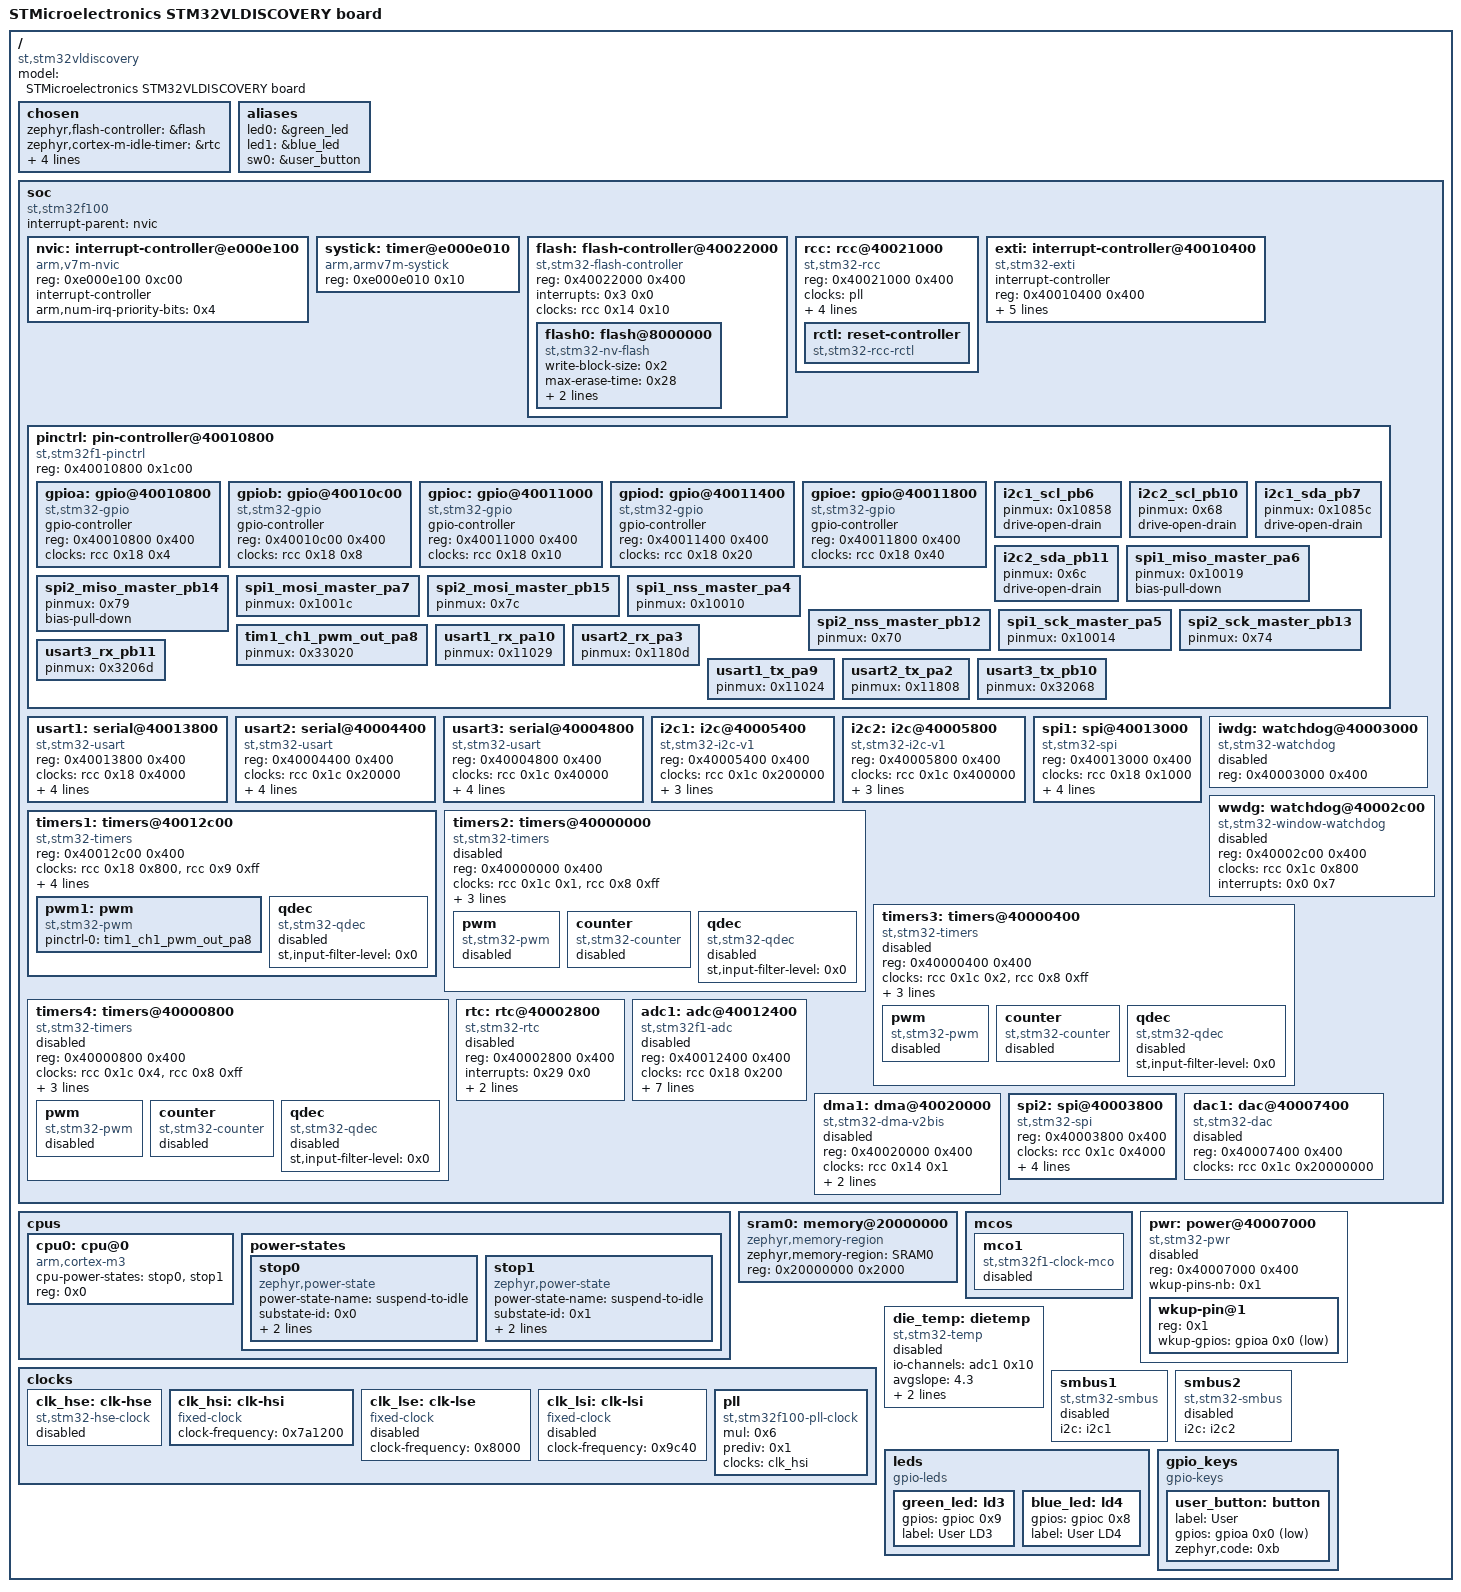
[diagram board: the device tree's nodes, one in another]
/dts-v1/;

/* node '/' defined in zephyr/dts/common/skeleton.dtsi:9 */
/ {
	#address-cells = < 0x1 >;                            /* in zephyr/dts/common/skeleton.dtsi:10 */
	#size-cells = < 0x1 >;                               /* in zephyr/dts/common/skeleton.dtsi:11 */
	model = "STMicroelectronics STM32VLDISCOVERY board"; /* in zephyr/boards/st/stm32vl_disco/stm32vl_disco.dts:13 */
	compatible = "st,stm32vldiscovery";                  /* in zephyr/boards/st/stm32vl_disco/stm32vl_disco.dts:14 */

	/* node '/chosen' defined in zephyr/dts/common/skeleton.dtsi:13 */
	chosen {
		zephyr,flash-controller = &flash;  /* in zephyr/dts/arm/st/f1/stm32f1.dtsi:25 */
		zephyr,cortex-m-idle-timer = &rtc; /* in zephyr/dts/arm/st/f1/stm32f1.dtsi:26 */
		zephyr,console = &usart1;          /* in zephyr/boards/st/stm32vl_disco/stm32vl_disco.dts:17 */
		zephyr,shell-uart = &usart1;       /* in zephyr/boards/st/stm32vl_disco/stm32vl_disco.dts:18 */
		zephyr,sram = &sram0;              /* in zephyr/boards/st/stm32vl_disco/stm32vl_disco.dts:19 */
		zephyr,flash = &flash0;            /* in zephyr/boards/st/stm32vl_disco/stm32vl_disco.dts:20 */
	};

	/* node '/aliases' defined in zephyr/dts/common/skeleton.dtsi:15 */
	aliases {
		led0 = &green_led;  /* in zephyr/boards/st/stm32vl_disco/stm32vl_disco.dts:48 */
		led1 = &blue_led;   /* in zephyr/boards/st/stm32vl_disco/stm32vl_disco.dts:49 */
		sw0 = &user_button; /* in zephyr/boards/st/stm32vl_disco/stm32vl_disco.dts:50 */
	};

	/* node '/soc' defined in zephyr/dts/arm/armv7-m.dtsi:6 */
	soc {
		#address-cells = < 0x1 >;     /* in zephyr/dts/arm/armv7-m.dtsi:7 */
		#size-cells = < 0x1 >;        /* in zephyr/dts/arm/armv7-m.dtsi:8 */
		interrupt-parent = < &nvic >; /* in zephyr/dts/arm/armv7-m.dtsi:10 */
		ranges;                       /* in zephyr/dts/arm/armv7-m.dtsi:11 */
		compatible = "st,stm32f100",
		             "st,stm32f1",
		             "simple-bus";    /* in zephyr/dts/arm/st/f1/stm32f100Xb.dtsi:27 */

		/* node '/soc/interrupt-controller@e000e100' defined in zephyr/dts/arm/armv7-m.dtsi:13 */
		nvic: interrupt-controller@e000e100 {
			#address-cells = < 0x1 >;            /* in zephyr/dts/arm/armv7-m.dtsi:14 */
			compatible = "arm,v7m-nvic";         /* in zephyr/dts/arm/armv7-m.dtsi:15 */
			reg = < 0xe000e100 0xc00 >;          /* in zephyr/dts/arm/armv7-m.dtsi:16 */
			interrupt-controller;                /* in zephyr/dts/arm/armv7-m.dtsi:17 */
			#interrupt-cells = < 0x2 >;          /* in zephyr/dts/arm/armv7-m.dtsi:18 */
			arm,num-irq-priority-bits = < 0x4 >; /* in zephyr/dts/arm/st/f1/stm32f1.dtsi:461 */
			phandle = < 0x1 >;                   /* in zephyr/dts/arm/armv7-m.dtsi:10 */
		};

		/* node '/soc/timer@e000e010' defined in zephyr/dts/arm/armv7-m.dtsi:21 */
		systick: timer@e000e010 {
			compatible = "arm,armv7m-systick"; /* in zephyr/dts/arm/armv7-m.dtsi:22 */
			reg = < 0xe000e010 0x10 >;         /* in zephyr/dts/arm/armv7-m.dtsi:23 */
		};

		/* node '/soc/flash-controller@40022000' defined in zephyr/dts/arm/st/f1/stm32f1.dtsi:107 */
		flash: flash-controller@40022000 {
			compatible = "st,stm32-flash-controller",
			             "st,stm32f1-flash-controller"; /* in zephyr/dts/arm/st/f1/stm32f1.dtsi:108 */
			reg = < 0x40022000 0x400 >;                 /* in zephyr/dts/arm/st/f1/stm32f1.dtsi:109 */
			interrupts = < 0x3 0x0 >;                   /* in zephyr/dts/arm/st/f1/stm32f1.dtsi:110 */
			clocks = < &rcc 0x14 0x10 >;                /* in zephyr/dts/arm/st/f1/stm32f1.dtsi:111 */
			#address-cells = < 0x1 >;                   /* in zephyr/dts/arm/st/f1/stm32f1.dtsi:113 */
			#size-cells = < 0x1 >;                      /* in zephyr/dts/arm/st/f1/stm32f1.dtsi:114 */

			/* node '/soc/flash-controller@40022000/flash@8000000' defined in zephyr/dts/arm/st/f1/stm32f1.dtsi:116 */
			flash0: flash@8000000 {
				compatible = "st,stm32-nv-flash",
				             "soc-nv-flash";      /* in zephyr/dts/arm/st/f1/stm32f1.dtsi:117 */
				write-block-size = < 0x2 >;       /* in zephyr/dts/arm/st/f1/stm32f1.dtsi:119 */
				max-erase-time = < 0x28 >;        /* in zephyr/dts/arm/st/f1/stm32f1.dtsi:121 */
				reg = < 0x8000000 0x20000 >;      /* in zephyr/dts/arm/st/f1/stm32f100Xb.dtsi:31 */
				erase-block-size = < 0x400 >;     /* in zephyr/dts/arm/st/f1/stm32f100Xb.dtsi:32 */
			};
		};

		/* node '/soc/rcc@40021000' defined in zephyr/dts/arm/st/f1/stm32f1.dtsi:125 */
		rcc: rcc@40021000 {
			compatible = "st,stm32-rcc";     /* in zephyr/dts/arm/st/f1/stm32f1.dtsi:126 */
			#clock-cells = < 0x2 >;          /* in zephyr/dts/arm/st/f1/stm32f1.dtsi:127 */
			reg = < 0x40021000 0x400 >;      /* in zephyr/dts/arm/st/f1/stm32f1.dtsi:128 */
			clocks = < &pll >;               /* in zephyr/boards/st/stm32vl_disco/stm32vl_disco.dts:66 */
			clock-frequency = < 0x16e3600 >; /* in zephyr/boards/st/stm32vl_disco/stm32vl_disco.dts:67 */
			ahb-prescaler = < 0x1 >;         /* in zephyr/boards/st/stm32vl_disco/stm32vl_disco.dts:68 */
			apb1-prescaler = < 0x2 >;        /* in zephyr/boards/st/stm32vl_disco/stm32vl_disco.dts:69 */
			apb2-prescaler = < 0x1 >;        /* in zephyr/boards/st/stm32vl_disco/stm32vl_disco.dts:70 */
			phandle = < 0x2 >;               /* in zephyr/dts/arm/st/f1/stm32f1.dtsi:111 */

			/* node '/soc/rcc@40021000/reset-controller' defined in zephyr/dts/arm/st/f1/stm32f1.dtsi:130 */
			rctl: reset-controller {
				compatible = "st,stm32-rcc-rctl"; /* in zephyr/dts/arm/st/f1/stm32f1.dtsi:131 */
				#reset-cells = < 0x1 >;           /* in zephyr/dts/arm/st/f1/stm32f1.dtsi:132 */
				phandle = < 0x4 >;                /* in zephyr/dts/arm/st/f1/stm32f1.dtsi:202 */
			};
		};

		/* node '/soc/interrupt-controller@40010400' defined in zephyr/dts/arm/st/f1/stm32f1.dtsi:136 */
		exti: interrupt-controller@40010400 {
			compatible = "st,stm32-exti";  /* in zephyr/dts/arm/st/f1/stm32f1.dtsi:137 */
			interrupt-controller;          /* in zephyr/dts/arm/st/f1/stm32f1.dtsi:138 */
			#interrupt-cells = < 0x1 >;    /* in zephyr/dts/arm/st/f1/stm32f1.dtsi:139 */
			#address-cells = < 0x0 >;      /* in zephyr/dts/arm/st/f1/stm32f1.dtsi:140 */
			reg = < 0x40010400 0x400 >;    /* in zephyr/dts/arm/st/f1/stm32f1.dtsi:141 */
			num-lines = < 0x20 >;          /* in zephyr/dts/arm/st/f1/stm32f1.dtsi:142 */
			interrupts = < 0x6 0x0 >,
			             < 0x7 0x0 >,
			             < 0x8 0x0 >,
			             < 0x9 0x0 >,
			             < 0xa 0x0 >,
			             < 0x17 0x0 >,
			             < 0x28 0x0 >;     /* in zephyr/dts/arm/st/f1/stm32f1.dtsi:143 */
			interrupt-names = "line0",
			                  "line1",
			                  "line2",
			                  "line3",
			                  "line4",
			                  "line5-9",
			                  "line10-15"; /* in zephyr/dts/arm/st/f1/stm32f1.dtsi:145 */
			line-ranges = < 0x0 0x1 >,
			              < 0x1 0x1 >,
			              < 0x2 0x1 >,
			              < 0x3 0x1 >,
			              < 0x4 0x1 >,
			              < 0x5 0x5 >,
			              < 0xa 0x6 >;     /* in zephyr/dts/arm/st/f1/stm32f1.dtsi:147 */
		};

		/* node '/soc/pin-controller@40010800' defined in zephyr/dts/arm/st/f1/stm32f1.dtsi:151 */
		pinctrl: pin-controller@40010800 {
			compatible = "st,stm32f1-pinctrl"; /* in zephyr/dts/arm/st/f1/stm32f1.dtsi:152 */
			#address-cells = < 0x1 >;          /* in zephyr/dts/arm/st/f1/stm32f1.dtsi:153 */
			#size-cells = < 0x1 >;             /* in zephyr/dts/arm/st/f1/stm32f1.dtsi:154 */
			reg = < 0x40010800 0x1c00 >;       /* in zephyr/dts/arm/st/f1/stm32f1.dtsi:155 */

			/* node '/soc/pin-controller@40010800/gpio@40010800' defined in zephyr/dts/arm/st/f1/stm32f1.dtsi:157 */
			gpioa: gpio@40010800 {
				compatible = "st,stm32-gpio"; /* in zephyr/dts/arm/st/f1/stm32f1.dtsi:158 */
				gpio-controller;              /* in zephyr/dts/arm/st/f1/stm32f1.dtsi:159 */
				#gpio-cells = < 0x2 >;        /* in zephyr/dts/arm/st/f1/stm32f1.dtsi:160 */
				reg = < 0x40010800 0x400 >;   /* in zephyr/dts/arm/st/f1/stm32f1.dtsi:161 */
				clocks = < &rcc 0x18 0x4 >;   /* in zephyr/dts/arm/st/f1/stm32f1.dtsi:162 */
				phandle = < 0x1b >;           /* in zephyr/dts/arm/st/f1/stm32f1.dtsi:430 */
			};

			/* node '/soc/pin-controller@40010800/gpio@40010c00' defined in zephyr/dts/arm/st/f1/stm32f1.dtsi:165 */
			gpiob: gpio@40010c00 {
				compatible = "st,stm32-gpio"; /* in zephyr/dts/arm/st/f1/stm32f1.dtsi:166 */
				gpio-controller;              /* in zephyr/dts/arm/st/f1/stm32f1.dtsi:167 */
				#gpio-cells = < 0x2 >;        /* in zephyr/dts/arm/st/f1/stm32f1.dtsi:168 */
				reg = < 0x40010c00 0x400 >;   /* in zephyr/dts/arm/st/f1/stm32f1.dtsi:169 */
				clocks = < &rcc 0x18 0x8 >;   /* in zephyr/dts/arm/st/f1/stm32f1.dtsi:170 */
			};

			/* node '/soc/pin-controller@40010800/gpio@40011000' defined in zephyr/dts/arm/st/f1/stm32f1.dtsi:173 */
			gpioc: gpio@40011000 {
				compatible = "st,stm32-gpio"; /* in zephyr/dts/arm/st/f1/stm32f1.dtsi:174 */
				gpio-controller;              /* in zephyr/dts/arm/st/f1/stm32f1.dtsi:175 */
				#gpio-cells = < 0x2 >;        /* in zephyr/dts/arm/st/f1/stm32f1.dtsi:176 */
				reg = < 0x40011000 0x400 >;   /* in zephyr/dts/arm/st/f1/stm32f1.dtsi:177 */
				clocks = < &rcc 0x18 0x10 >;  /* in zephyr/dts/arm/st/f1/stm32f1.dtsi:178 */
				phandle = < 0x1f >;           /* in zephyr/boards/st/stm32vl_disco/stm32vl_disco.dts:27 */
			};

			/* node '/soc/pin-controller@40010800/gpio@40011400' defined in zephyr/dts/arm/st/f1/stm32f1.dtsi:181 */
			gpiod: gpio@40011400 {
				compatible = "st,stm32-gpio"; /* in zephyr/dts/arm/st/f1/stm32f1.dtsi:182 */
				gpio-controller;              /* in zephyr/dts/arm/st/f1/stm32f1.dtsi:183 */
				#gpio-cells = < 0x2 >;        /* in zephyr/dts/arm/st/f1/stm32f1.dtsi:184 */
				reg = < 0x40011400 0x400 >;   /* in zephyr/dts/arm/st/f1/stm32f1.dtsi:185 */
				clocks = < &rcc 0x18 0x20 >;  /* in zephyr/dts/arm/st/f1/stm32f1.dtsi:186 */
			};

			/* node '/soc/pin-controller@40010800/gpio@40011800' defined in zephyr/dts/arm/st/f1/stm32f1.dtsi:189 */
			gpioe: gpio@40011800 {
				compatible = "st,stm32-gpio"; /* in zephyr/dts/arm/st/f1/stm32f1.dtsi:190 */
				gpio-controller;              /* in zephyr/dts/arm/st/f1/stm32f1.dtsi:191 */
				#gpio-cells = < 0x2 >;        /* in zephyr/dts/arm/st/f1/stm32f1.dtsi:192 */
				reg = < 0x40011800 0x400 >;   /* in zephyr/dts/arm/st/f1/stm32f1.dtsi:193 */
				clocks = < &rcc 0x18 0x40 >;  /* in zephyr/dts/arm/st/f1/stm32f1.dtsi:194 */
			};

			/* node '/soc/pin-controller@40010800/i2c1_scl_pb6' defined in modules/hal/stm32/dts/st/f1/stm32f100r(8-b)tx-pinctrl.dtsi:297 */
			i2c1_scl_pb6: i2c1_scl_pb6 {
				pinmux = < 0x10858 >; /* in modules/hal/stm32/dts/st/f1/stm32f100r(8-b)tx-pinctrl.dtsi:298 */
				drive-open-drain;     /* in modules/hal/stm32/dts/st/f1/stm32f100r(8-b)tx-pinctrl.dtsi:299 */
				phandle = < 0xb >;    /* in zephyr/boards/st/stm32vl_disco/stm32vl_disco.dts:95 */
			};

			/* node '/soc/pin-controller@40010800/i2c2_scl_pb10' defined in modules/hal/stm32/dts/st/f1/stm32f100r(8-b)tx-pinctrl.dtsi:307 */
			i2c2_scl_pb10: i2c2_scl_pb10 {
				pinmux = < 0x68 >; /* in modules/hal/stm32/dts/st/f1/stm32f100r(8-b)tx-pinctrl.dtsi:308 */
				drive-open-drain;  /* in modules/hal/stm32/dts/st/f1/stm32f100r(8-b)tx-pinctrl.dtsi:309 */
				phandle = < 0xd >; /* in zephyr/boards/st/stm32vl_disco/stm32vl_disco.dts:102 */
			};

			/* node '/soc/pin-controller@40010800/i2c1_sda_pb7' defined in modules/hal/stm32/dts/st/f1/stm32f100r(8-b)tx-pinctrl.dtsi:314 */
			i2c1_sda_pb7: i2c1_sda_pb7 {
				pinmux = < 0x1085c >; /* in modules/hal/stm32/dts/st/f1/stm32f100r(8-b)tx-pinctrl.dtsi:315 */
				drive-open-drain;     /* in modules/hal/stm32/dts/st/f1/stm32f100r(8-b)tx-pinctrl.dtsi:316 */
				phandle = < 0xc >;    /* in zephyr/boards/st/stm32vl_disco/stm32vl_disco.dts:95 */
			};

			/* node '/soc/pin-controller@40010800/i2c2_sda_pb11' defined in modules/hal/stm32/dts/st/f1/stm32f100r(8-b)tx-pinctrl.dtsi:324 */
			i2c2_sda_pb11: i2c2_sda_pb11 {
				pinmux = < 0x6c >; /* in modules/hal/stm32/dts/st/f1/stm32f100r(8-b)tx-pinctrl.dtsi:325 */
				drive-open-drain;  /* in modules/hal/stm32/dts/st/f1/stm32f100r(8-b)tx-pinctrl.dtsi:326 */
				phandle = < 0xe >; /* in zephyr/boards/st/stm32vl_disco/stm32vl_disco.dts:102 */
			};

			/* node '/soc/pin-controller@40010800/spi1_miso_master_pa6' defined in modules/hal/stm32/dts/st/f1/stm32f100r(8-b)tx-pinctrl.dtsi:365 */
			spi1_miso_master_pa6: spi1_miso_master_pa6 {
				pinmux = < 0x10019 >; /* in modules/hal/stm32/dts/st/f1/stm32f100r(8-b)tx-pinctrl.dtsi:366 */
				bias-pull-down;       /* in modules/hal/stm32/dts/st/f1/stm32f100r(8-b)tx-pinctrl.dtsi:367 */
				phandle = < 0x11 >;   /* in zephyr/boards/st/stm32vl_disco/stm32vl_disco.dts:109 */
			};

			/* node '/soc/pin-controller@40010800/spi2_miso_master_pb14' defined in modules/hal/stm32/dts/st/f1/stm32f100r(8-b)tx-pinctrl.dtsi:375 */
			spi2_miso_master_pb14: spi2_miso_master_pb14 {
				pinmux = < 0x79 >;  /* in modules/hal/stm32/dts/st/f1/stm32f100r(8-b)tx-pinctrl.dtsi:376 */
				bias-pull-down;     /* in modules/hal/stm32/dts/st/f1/stm32f100r(8-b)tx-pinctrl.dtsi:377 */
				phandle = < 0x16 >; /* in zephyr/boards/st/stm32vl_disco/stm32vl_disco.dts:116 */
			};

			/* node '/soc/pin-controller@40010800/spi1_mosi_master_pa7' defined in modules/hal/stm32/dts/st/f1/stm32f100r(8-b)tx-pinctrl.dtsi:382 */
			spi1_mosi_master_pa7: spi1_mosi_master_pa7 {
				pinmux = < 0x1001c >; /* in modules/hal/stm32/dts/st/f1/stm32f100r(8-b)tx-pinctrl.dtsi:383 */
				phandle = < 0x12 >;   /* in zephyr/boards/st/stm32vl_disco/stm32vl_disco.dts:109 */
			};

			/* node '/soc/pin-controller@40010800/spi2_mosi_master_pb15' defined in modules/hal/stm32/dts/st/f1/stm32f100r(8-b)tx-pinctrl.dtsi:390 */
			spi2_mosi_master_pb15: spi2_mosi_master_pb15 {
				pinmux = < 0x7c >;  /* in modules/hal/stm32/dts/st/f1/stm32f100r(8-b)tx-pinctrl.dtsi:391 */
				phandle = < 0x17 >; /* in zephyr/boards/st/stm32vl_disco/stm32vl_disco.dts:116 */
			};

			/* node '/soc/pin-controller@40010800/spi1_nss_master_pa4' defined in modules/hal/stm32/dts/st/f1/stm32f100r(8-b)tx-pinctrl.dtsi:396 */
			spi1_nss_master_pa4: spi1_nss_master_pa4 {
				pinmux = < 0x10010 >; /* in modules/hal/stm32/dts/st/f1/stm32f100r(8-b)tx-pinctrl.dtsi:397 */
				phandle = < 0xf >;    /* in zephyr/boards/st/stm32vl_disco/stm32vl_disco.dts:109 */
			};

			/* node '/soc/pin-controller@40010800/spi2_nss_master_pb12' defined in modules/hal/stm32/dts/st/f1/stm32f100r(8-b)tx-pinctrl.dtsi:404 */
			spi2_nss_master_pb12: spi2_nss_master_pb12 {
				pinmux = < 0x70 >;  /* in modules/hal/stm32/dts/st/f1/stm32f100r(8-b)tx-pinctrl.dtsi:405 */
				phandle = < 0x14 >; /* in zephyr/boards/st/stm32vl_disco/stm32vl_disco.dts:116 */
			};

			/* node '/soc/pin-controller@40010800/spi1_sck_master_pa5' defined in modules/hal/stm32/dts/st/f1/stm32f100r(8-b)tx-pinctrl.dtsi:410 */
			spi1_sck_master_pa5: spi1_sck_master_pa5 {
				pinmux = < 0x10014 >; /* in modules/hal/stm32/dts/st/f1/stm32f100r(8-b)tx-pinctrl.dtsi:411 */
				phandle = < 0x10 >;   /* in zephyr/boards/st/stm32vl_disco/stm32vl_disco.dts:109 */
			};

			/* node '/soc/pin-controller@40010800/spi2_sck_master_pb13' defined in modules/hal/stm32/dts/st/f1/stm32f100r(8-b)tx-pinctrl.dtsi:418 */
			spi2_sck_master_pb13: spi2_sck_master_pb13 {
				pinmux = < 0x74 >;  /* in modules/hal/stm32/dts/st/f1/stm32f100r(8-b)tx-pinctrl.dtsi:419 */
				phandle = < 0x15 >; /* in zephyr/boards/st/stm32vl_disco/stm32vl_disco.dts:116 */
			};

			/* node '/soc/pin-controller@40010800/tim1_ch1_pwm_out_pa8' defined in modules/hal/stm32/dts/st/f1/stm32f100r(8-b)tx-pinctrl.dtsi:739 */
			tim1_ch1_pwm_out_pa8: tim1_ch1_pwm_out_pa8 {
				pinmux = < 0x33020 >; /* in modules/hal/stm32/dts/st/f1/stm32f100r(8-b)tx-pinctrl.dtsi:740 */
				phandle = < 0x13 >;   /* in zephyr/boards/st/stm32vl_disco/stm32vl_disco.dts:128 */
			};

			/* node '/soc/pin-controller@40010800/usart1_rx_pa10' defined in modules/hal/stm32/dts/st/f1/stm32f100r(8-b)tx-pinctrl.dtsi:1009 */
			usart1_rx_pa10: usart1_rx_pa10 {
				pinmux = < 0x11029 >; /* in modules/hal/stm32/dts/st/f1/stm32f100r(8-b)tx-pinctrl.dtsi:1010 */
				phandle = < 0x6 >;    /* in zephyr/boards/st/stm32vl_disco/stm32vl_disco.dts:74 */
			};

			/* node '/soc/pin-controller@40010800/usart2_rx_pa3' defined in modules/hal/stm32/dts/st/f1/stm32f100r(8-b)tx-pinctrl.dtsi:1017 */
			usart2_rx_pa3: usart2_rx_pa3 {
				pinmux = < 0x1180d >; /* in modules/hal/stm32/dts/st/f1/stm32f100r(8-b)tx-pinctrl.dtsi:1018 */
				phandle = < 0x8 >;    /* in zephyr/boards/st/stm32vl_disco/stm32vl_disco.dts:81 */
			};

			/* node '/soc/pin-controller@40010800/usart3_rx_pb11' defined in modules/hal/stm32/dts/st/f1/stm32f100r(8-b)tx-pinctrl.dtsi:1021 */
			usart3_rx_pb11: usart3_rx_pb11 {
				pinmux = < 0x3206d >; /* in modules/hal/stm32/dts/st/f1/stm32f100r(8-b)tx-pinctrl.dtsi:1022 */
				phandle = < 0xa >;    /* in zephyr/boards/st/stm32vl_disco/stm32vl_disco.dts:88 */
			};

			/* node '/soc/pin-controller@40010800/usart1_tx_pa9' defined in modules/hal/stm32/dts/st/f1/stm32f100r(8-b)tx-pinctrl.dtsi:1031 */
			usart1_tx_pa9: usart1_tx_pa9 {
				pinmux = < 0x11024 >; /* in modules/hal/stm32/dts/st/f1/stm32f100r(8-b)tx-pinctrl.dtsi:1032 */
				phandle = < 0x5 >;    /* in zephyr/boards/st/stm32vl_disco/stm32vl_disco.dts:74 */
			};

			/* node '/soc/pin-controller@40010800/usart2_tx_pa2' defined in modules/hal/stm32/dts/st/f1/stm32f100r(8-b)tx-pinctrl.dtsi:1039 */
			usart2_tx_pa2: usart2_tx_pa2 {
				pinmux = < 0x11808 >; /* in modules/hal/stm32/dts/st/f1/stm32f100r(8-b)tx-pinctrl.dtsi:1040 */
				phandle = < 0x7 >;    /* in zephyr/boards/st/stm32vl_disco/stm32vl_disco.dts:81 */
			};

			/* node '/soc/pin-controller@40010800/usart3_tx_pb10' defined in modules/hal/stm32/dts/st/f1/stm32f100r(8-b)tx-pinctrl.dtsi:1043 */
			usart3_tx_pb10: usart3_tx_pb10 {
				pinmux = < 0x32068 >; /* in modules/hal/stm32/dts/st/f1/stm32f100r(8-b)tx-pinctrl.dtsi:1044 */
				phandle = < 0x9 >;    /* in zephyr/boards/st/stm32vl_disco/stm32vl_disco.dts:88 */
			};
		};

		/* node '/soc/serial@40013800' defined in zephyr/dts/arm/st/f1/stm32f1.dtsi:198 */
		usart1: serial@40013800 {
			compatible = "st,stm32-usart",
			             "st,stm32-uart";                   /* in zephyr/dts/arm/st/f1/stm32f1.dtsi:199 */
			reg = < 0x40013800 0x400 >;                     /* in zephyr/dts/arm/st/f1/stm32f1.dtsi:200 */
			clocks = < &rcc 0x18 0x4000 >;                  /* in zephyr/dts/arm/st/f1/stm32f1.dtsi:201 */
			resets = < &rctl 0x18e >;                       /* in zephyr/dts/arm/st/f1/stm32f1.dtsi:202 */
			interrupts = < 0x25 0x0 >;                      /* in zephyr/dts/arm/st/f1/stm32f1.dtsi:203 */
			pinctrl-0 = < &usart1_tx_pa9 &usart1_rx_pa10 >; /* in zephyr/boards/st/stm32vl_disco/stm32vl_disco.dts:74 */
			pinctrl-names = "default";                      /* in zephyr/boards/st/stm32vl_disco/stm32vl_disco.dts:75 */
			current-speed = < 0x1c200 >;                    /* in zephyr/boards/st/stm32vl_disco/stm32vl_disco.dts:76 */
			status = "okay";                                /* in zephyr/boards/st/stm32vl_disco/stm32vl_disco.dts:77 */
		};

		/* node '/soc/serial@40004400' defined in zephyr/dts/arm/st/f1/stm32f1.dtsi:207 */
		usart2: serial@40004400 {
			compatible = "st,stm32-usart",
			             "st,stm32-uart";                  /* in zephyr/dts/arm/st/f1/stm32f1.dtsi:208 */
			reg = < 0x40004400 0x400 >;                    /* in zephyr/dts/arm/st/f1/stm32f1.dtsi:209 */
			clocks = < &rcc 0x1c 0x20000 >;                /* in zephyr/dts/arm/st/f1/stm32f1.dtsi:210 */
			resets = < &rctl 0x211 >;                      /* in zephyr/dts/arm/st/f1/stm32f1.dtsi:211 */
			interrupts = < 0x26 0x0 >;                     /* in zephyr/dts/arm/st/f1/stm32f1.dtsi:212 */
			pinctrl-0 = < &usart2_tx_pa2 &usart2_rx_pa3 >; /* in zephyr/boards/st/stm32vl_disco/stm32vl_disco.dts:81 */
			pinctrl-names = "default";                     /* in zephyr/boards/st/stm32vl_disco/stm32vl_disco.dts:82 */
			current-speed = < 0x1c200 >;                   /* in zephyr/boards/st/stm32vl_disco/stm32vl_disco.dts:83 */
			status = "okay";                               /* in zephyr/boards/st/stm32vl_disco/stm32vl_disco.dts:84 */
		};

		/* node '/soc/serial@40004800' defined in zephyr/dts/arm/st/f1/stm32f1.dtsi:216 */
		usart3: serial@40004800 {
			compatible = "st,stm32-usart",
			             "st,stm32-uart";                    /* in zephyr/dts/arm/st/f1/stm32f1.dtsi:217 */
			reg = < 0x40004800 0x400 >;                      /* in zephyr/dts/arm/st/f1/stm32f1.dtsi:218 */
			clocks = < &rcc 0x1c 0x40000 >;                  /* in zephyr/dts/arm/st/f1/stm32f1.dtsi:219 */
			resets = < &rctl 0x212 >;                        /* in zephyr/dts/arm/st/f1/stm32f1.dtsi:220 */
			interrupts = < 0x27 0x0 >;                       /* in zephyr/dts/arm/st/f1/stm32f1.dtsi:221 */
			pinctrl-0 = < &usart3_tx_pb10 &usart3_rx_pb11 >; /* in zephyr/boards/st/stm32vl_disco/stm32vl_disco.dts:88 */
			pinctrl-names = "default";                       /* in zephyr/boards/st/stm32vl_disco/stm32vl_disco.dts:89 */
			current-speed = < 0x1c200 >;                     /* in zephyr/boards/st/stm32vl_disco/stm32vl_disco.dts:90 */
			status = "okay";                                 /* in zephyr/boards/st/stm32vl_disco/stm32vl_disco.dts:91 */
		};

		/* node '/soc/i2c@40005400' defined in zephyr/dts/arm/st/f1/stm32f1.dtsi:225 */
		i2c1: i2c@40005400 {
			compatible = "st,stm32-i2c-v1";              /* in zephyr/dts/arm/st/f1/stm32f1.dtsi:226 */
			#address-cells = < 0x1 >;                    /* in zephyr/dts/arm/st/f1/stm32f1.dtsi:228 */
			#size-cells = < 0x0 >;                       /* in zephyr/dts/arm/st/f1/stm32f1.dtsi:229 */
			reg = < 0x40005400 0x400 >;                  /* in zephyr/dts/arm/st/f1/stm32f1.dtsi:230 */
			clocks = < &rcc 0x1c 0x200000 >;             /* in zephyr/dts/arm/st/f1/stm32f1.dtsi:231 */
			interrupts = < 0x1f 0x0 >,
			             < 0x20 0x0 >;                   /* in zephyr/dts/arm/st/f1/stm32f1.dtsi:232 */
			interrupt-names = "event",
			                  "error";                   /* in zephyr/dts/arm/st/f1/stm32f1.dtsi:233 */
			pinctrl-0 = < &i2c1_scl_pb6 &i2c1_sda_pb7 >; /* in zephyr/boards/st/stm32vl_disco/stm32vl_disco.dts:95 */
			pinctrl-names = "default";                   /* in zephyr/boards/st/stm32vl_disco/stm32vl_disco.dts:96 */
			status = "okay";                             /* in zephyr/boards/st/stm32vl_disco/stm32vl_disco.dts:97 */
			clock-frequency = < 0x61a80 >;               /* in zephyr/boards/st/stm32vl_disco/stm32vl_disco.dts:98 */
			phandle = < 0x1d >;                          /* in zephyr/dts/arm/st/f1/stm32f1.dtsi:447 */
		};

		/* node '/soc/i2c@40005800' defined in zephyr/dts/arm/st/f1/stm32f1.dtsi:237 */
		i2c2: i2c@40005800 {
			compatible = "st,stm32-i2c-v1";                /* in zephyr/dts/arm/st/f1/stm32f1.dtsi:238 */
			#address-cells = < 0x1 >;                      /* in zephyr/dts/arm/st/f1/stm32f1.dtsi:240 */
			#size-cells = < 0x0 >;                         /* in zephyr/dts/arm/st/f1/stm32f1.dtsi:241 */
			reg = < 0x40005800 0x400 >;                    /* in zephyr/dts/arm/st/f1/stm32f1.dtsi:242 */
			clocks = < &rcc 0x1c 0x400000 >;               /* in zephyr/dts/arm/st/f1/stm32f1.dtsi:243 */
			interrupts = < 0x21 0x0 >,
			             < 0x22 0x0 >;                     /* in zephyr/dts/arm/st/f1/stm32f1.dtsi:244 */
			interrupt-names = "event",
			                  "error";                     /* in zephyr/dts/arm/st/f1/stm32f1.dtsi:245 */
			pinctrl-0 = < &i2c2_scl_pb10 &i2c2_sda_pb11 >; /* in zephyr/boards/st/stm32vl_disco/stm32vl_disco.dts:102 */
			pinctrl-names = "default";                     /* in zephyr/boards/st/stm32vl_disco/stm32vl_disco.dts:103 */
			status = "okay";                               /* in zephyr/boards/st/stm32vl_disco/stm32vl_disco.dts:104 */
			clock-frequency = < 0x61a80 >;                 /* in zephyr/boards/st/stm32vl_disco/stm32vl_disco.dts:105 */
			phandle = < 0x1e >;                            /* in zephyr/dts/arm/st/f1/stm32f1.dtsi:455 */
		};

		/* node '/soc/spi@40013000' defined in zephyr/dts/arm/st/f1/stm32f1.dtsi:249 */
		spi1: spi@40013000 {
			compatible = "st,stm32-spi";                                                                           /* in zephyr/dts/arm/st/f1/stm32f1.dtsi:250 */
			#address-cells = < 0x1 >;                                                                              /* in zephyr/dts/arm/st/f1/stm32f1.dtsi:251 */
			#size-cells = < 0x0 >;                                                                                 /* in zephyr/dts/arm/st/f1/stm32f1.dtsi:252 */
			reg = < 0x40013000 0x400 >;                                                                            /* in zephyr/dts/arm/st/f1/stm32f1.dtsi:253 */
			clocks = < &rcc 0x18 0x1000 >;                                                                         /* in zephyr/dts/arm/st/f1/stm32f1.dtsi:254 */
			interrupts = < 0x23 0x5 >;                                                                             /* in zephyr/dts/arm/st/f1/stm32f1.dtsi:255 */
			pinctrl-0 = < &spi1_nss_master_pa4 &spi1_sck_master_pa5 &spi1_miso_master_pa6 &spi1_mosi_master_pa7 >; /* in zephyr/boards/st/stm32vl_disco/stm32vl_disco.dts:109 */
			pinctrl-names = "default";                                                                             /* in zephyr/boards/st/stm32vl_disco/stm32vl_disco.dts:111 */
			status = "okay";                                                                                       /* in zephyr/boards/st/stm32vl_disco/stm32vl_disco.dts:112 */
		};

		/* node '/soc/watchdog@40003000' defined in zephyr/dts/arm/st/f1/stm32f1.dtsi:259 */
		iwdg: watchdog@40003000 {
			compatible = "st,stm32-watchdog"; /* in zephyr/dts/arm/st/f1/stm32f1.dtsi:260 */
			reg = < 0x40003000 0x400 >;       /* in zephyr/dts/arm/st/f1/stm32f1.dtsi:261 */
			status = "disabled";              /* in zephyr/dts/arm/st/f1/stm32f1.dtsi:262 */
		};

		/* node '/soc/watchdog@40002c00' defined in zephyr/dts/arm/st/f1/stm32f1.dtsi:265 */
		wwdg: watchdog@40002c00 {
			compatible = "st,stm32-window-watchdog"; /* in zephyr/dts/arm/st/f1/stm32f1.dtsi:266 */
			reg = < 0x40002c00 0x400 >;              /* in zephyr/dts/arm/st/f1/stm32f1.dtsi:267 */
			clocks = < &rcc 0x1c 0x800 >;            /* in zephyr/dts/arm/st/f1/stm32f1.dtsi:268 */
			interrupts = < 0x0 0x7 >;                /* in zephyr/dts/arm/st/f1/stm32f1.dtsi:269 */
			status = "disabled";                     /* in zephyr/dts/arm/st/f1/stm32f1.dtsi:270 */
		};

		/* node '/soc/timers@40012c00' defined in zephyr/dts/arm/st/f1/stm32f1.dtsi:273 */
		timers1: timers@40012c00 {
			compatible = "st,stm32-timers"; /* in zephyr/dts/arm/st/f1/stm32f1.dtsi:274 */
			reg = < 0x40012c00 0x400 >;     /* in zephyr/dts/arm/st/f1/stm32f1.dtsi:275 */
			clocks = < &rcc 0x18 0x800 >,
			         < &rcc 0x9 0xff >;     /* in zephyr/dts/arm/st/f1/stm32f1.dtsi:276 */
			resets = < &rctl 0x18b >;       /* in zephyr/dts/arm/st/f1/stm32f1.dtsi:278 */
			interrupts = < 0x18 0x0 >,
			             < 0x19 0x0 >,
			             < 0x1a 0x0 >,
			             < 0x1b 0x0 >;      /* in zephyr/dts/arm/st/f1/stm32f1.dtsi:279 */
			interrupt-names = "brk",
			                  "up",
			                  "trgcom",
			                  "cc";         /* in zephyr/dts/arm/st/f1/stm32f1.dtsi:280 */
			st,prescaler = < 0x2710 >;      /* in zephyr/boards/st/stm32vl_disco/stm32vl_disco.dts:123 */
			status = "okay";                /* in zephyr/boards/st/stm32vl_disco/stm32vl_disco.dts:124 */

			/* node '/soc/timers@40012c00/pwm' defined in zephyr/dts/arm/st/f1/stm32f1.dtsi:284 */
			pwm1: pwm {
				compatible = "st,stm32-pwm";           /* in zephyr/dts/arm/st/f1/stm32f1.dtsi:285 */
				#pwm-cells = < 0x3 >;                  /* in zephyr/dts/arm/st/f1/stm32f1.dtsi:287 */
				status = "okay";                       /* in zephyr/boards/st/stm32vl_disco/stm32vl_disco.dts:127 */
				pinctrl-0 = < &tim1_ch1_pwm_out_pa8 >; /* in zephyr/boards/st/stm32vl_disco/stm32vl_disco.dts:128 */
				pinctrl-names = "default";             /* in zephyr/boards/st/stm32vl_disco/stm32vl_disco.dts:129 */
			};

			/* node '/soc/timers@40012c00/qdec' defined in zephyr/dts/arm/st/f1/stm32f1.dtsi:290 */
			qdec {
				compatible = "st,stm32-qdec";    /* in zephyr/dts/arm/st/f1/stm32f1.dtsi:291 */
				st,input-filter-level = < 0x0 >; /* in zephyr/dts/arm/st/f1/stm32f1.dtsi:292 */
				status = "disabled";             /* in zephyr/dts/arm/st/f1/stm32f1.dtsi:293 */
			};
		};

		/* node '/soc/timers@40000000' defined in zephyr/dts/arm/st/f1/stm32f1.dtsi:297 */
		timers2: timers@40000000 {
			compatible = "st,stm32-timers"; /* in zephyr/dts/arm/st/f1/stm32f1.dtsi:298 */
			reg = < 0x40000000 0x400 >;     /* in zephyr/dts/arm/st/f1/stm32f1.dtsi:299 */
			clocks = < &rcc 0x1c 0x1 >,
			         < &rcc 0x8 0xff >;     /* in zephyr/dts/arm/st/f1/stm32f1.dtsi:300 */
			resets = < &rctl 0x200 >;       /* in zephyr/dts/arm/st/f1/stm32f1.dtsi:302 */
			interrupts = < 0x1c 0x0 >;      /* in zephyr/dts/arm/st/f1/stm32f1.dtsi:303 */
			interrupt-names = "global";     /* in zephyr/dts/arm/st/f1/stm32f1.dtsi:304 */
			st,prescaler = < 0x0 >;         /* in zephyr/dts/arm/st/f1/stm32f1.dtsi:305 */
			status = "disabled";            /* in zephyr/dts/arm/st/f1/stm32f1.dtsi:306 */

			/* node '/soc/timers@40000000/pwm' defined in zephyr/dts/arm/st/f1/stm32f1.dtsi:308 */
			pwm {
				compatible = "st,stm32-pwm"; /* in zephyr/dts/arm/st/f1/stm32f1.dtsi:309 */
				status = "disabled";         /* in zephyr/dts/arm/st/f1/stm32f1.dtsi:310 */
				#pwm-cells = < 0x3 >;        /* in zephyr/dts/arm/st/f1/stm32f1.dtsi:311 */
			};

			/* node '/soc/timers@40000000/counter' defined in zephyr/dts/arm/st/f1/stm32f1.dtsi:314 */
			counter {
				compatible = "st,stm32-counter"; /* in zephyr/dts/arm/st/f1/stm32f1.dtsi:315 */
				status = "disabled";             /* in zephyr/dts/arm/st/f1/stm32f1.dtsi:316 */
			};

			/* node '/soc/timers@40000000/qdec' defined in zephyr/dts/arm/st/f1/stm32f1.dtsi:319 */
			qdec {
				compatible = "st,stm32-qdec";    /* in zephyr/dts/arm/st/f1/stm32f1.dtsi:320 */
				st,input-filter-level = < 0x0 >; /* in zephyr/dts/arm/st/f1/stm32f1.dtsi:321 */
				status = "disabled";             /* in zephyr/dts/arm/st/f1/stm32f1.dtsi:322 */
			};
		};

		/* node '/soc/timers@40000400' defined in zephyr/dts/arm/st/f1/stm32f1.dtsi:326 */
		timers3: timers@40000400 {
			compatible = "st,stm32-timers"; /* in zephyr/dts/arm/st/f1/stm32f1.dtsi:327 */
			reg = < 0x40000400 0x400 >;     /* in zephyr/dts/arm/st/f1/stm32f1.dtsi:328 */
			clocks = < &rcc 0x1c 0x2 >,
			         < &rcc 0x8 0xff >;     /* in zephyr/dts/arm/st/f1/stm32f1.dtsi:329 */
			resets = < &rctl 0x201 >;       /* in zephyr/dts/arm/st/f1/stm32f1.dtsi:331 */
			interrupts = < 0x1d 0x0 >;      /* in zephyr/dts/arm/st/f1/stm32f1.dtsi:332 */
			interrupt-names = "global";     /* in zephyr/dts/arm/st/f1/stm32f1.dtsi:333 */
			st,prescaler = < 0x0 >;         /* in zephyr/dts/arm/st/f1/stm32f1.dtsi:334 */
			status = "disabled";            /* in zephyr/dts/arm/st/f1/stm32f1.dtsi:335 */

			/* node '/soc/timers@40000400/pwm' defined in zephyr/dts/arm/st/f1/stm32f1.dtsi:337 */
			pwm {
				compatible = "st,stm32-pwm"; /* in zephyr/dts/arm/st/f1/stm32f1.dtsi:338 */
				status = "disabled";         /* in zephyr/dts/arm/st/f1/stm32f1.dtsi:339 */
				#pwm-cells = < 0x3 >;        /* in zephyr/dts/arm/st/f1/stm32f1.dtsi:340 */
			};

			/* node '/soc/timers@40000400/counter' defined in zephyr/dts/arm/st/f1/stm32f1.dtsi:343 */
			counter {
				compatible = "st,stm32-counter"; /* in zephyr/dts/arm/st/f1/stm32f1.dtsi:344 */
				status = "disabled";             /* in zephyr/dts/arm/st/f1/stm32f1.dtsi:345 */
			};

			/* node '/soc/timers@40000400/qdec' defined in zephyr/dts/arm/st/f1/stm32f1.dtsi:348 */
			qdec {
				compatible = "st,stm32-qdec";    /* in zephyr/dts/arm/st/f1/stm32f1.dtsi:349 */
				st,input-filter-level = < 0x0 >; /* in zephyr/dts/arm/st/f1/stm32f1.dtsi:350 */
				status = "disabled";             /* in zephyr/dts/arm/st/f1/stm32f1.dtsi:351 */
			};
		};

		/* node '/soc/timers@40000800' defined in zephyr/dts/arm/st/f1/stm32f1.dtsi:355 */
		timers4: timers@40000800 {
			compatible = "st,stm32-timers"; /* in zephyr/dts/arm/st/f1/stm32f1.dtsi:356 */
			reg = < 0x40000800 0x400 >;     /* in zephyr/dts/arm/st/f1/stm32f1.dtsi:357 */
			clocks = < &rcc 0x1c 0x4 >,
			         < &rcc 0x8 0xff >;     /* in zephyr/dts/arm/st/f1/stm32f1.dtsi:358 */
			resets = < &rctl 0x202 >;       /* in zephyr/dts/arm/st/f1/stm32f1.dtsi:360 */
			interrupts = < 0x1e 0x0 >;      /* in zephyr/dts/arm/st/f1/stm32f1.dtsi:361 */
			interrupt-names = "global";     /* in zephyr/dts/arm/st/f1/stm32f1.dtsi:362 */
			st,prescaler = < 0x0 >;         /* in zephyr/dts/arm/st/f1/stm32f1.dtsi:363 */
			status = "disabled";            /* in zephyr/dts/arm/st/f1/stm32f1.dtsi:364 */

			/* node '/soc/timers@40000800/pwm' defined in zephyr/dts/arm/st/f1/stm32f1.dtsi:366 */
			pwm {
				compatible = "st,stm32-pwm"; /* in zephyr/dts/arm/st/f1/stm32f1.dtsi:367 */
				status = "disabled";         /* in zephyr/dts/arm/st/f1/stm32f1.dtsi:368 */
				#pwm-cells = < 0x3 >;        /* in zephyr/dts/arm/st/f1/stm32f1.dtsi:369 */
			};

			/* node '/soc/timers@40000800/counter' defined in zephyr/dts/arm/st/f1/stm32f1.dtsi:372 */
			counter {
				compatible = "st,stm32-counter"; /* in zephyr/dts/arm/st/f1/stm32f1.dtsi:373 */
				status = "disabled";             /* in zephyr/dts/arm/st/f1/stm32f1.dtsi:374 */
			};

			/* node '/soc/timers@40000800/qdec' defined in zephyr/dts/arm/st/f1/stm32f1.dtsi:377 */
			qdec {
				compatible = "st,stm32-qdec";    /* in zephyr/dts/arm/st/f1/stm32f1.dtsi:378 */
				st,input-filter-level = < 0x0 >; /* in zephyr/dts/arm/st/f1/stm32f1.dtsi:379 */
				status = "disabled";             /* in zephyr/dts/arm/st/f1/stm32f1.dtsi:380 */
			};
		};

		/* node '/soc/rtc@40002800' defined in zephyr/dts/arm/st/f1/stm32f1.dtsi:384 */
		rtc: rtc@40002800 {
			compatible = "st,stm32-rtc";       /* in zephyr/dts/arm/st/f1/stm32f1.dtsi:385 */
			reg = < 0x40002800 0x400 >;        /* in zephyr/dts/arm/st/f1/stm32f1.dtsi:386 */
			interrupts = < 0x29 0x0 >;         /* in zephyr/dts/arm/st/f1/stm32f1.dtsi:387 */
			clocks = < &rcc 0x1c 0x10000000 >; /* in zephyr/dts/arm/st/f1/stm32f1.dtsi:388 */
			prescaler = < 0x8000 >;            /* in zephyr/dts/arm/st/f1/stm32f1.dtsi:389 */
			status = "disabled";               /* in zephyr/dts/arm/st/f1/stm32f1.dtsi:390 */
		};

		/* node '/soc/adc@40012400' defined in zephyr/dts/arm/st/f1/stm32f1.dtsi:393 */
		adc1: adc@40012400 {
			compatible = "st,stm32f1-adc",
			             "st,stm32-adc";                               /* in zephyr/dts/arm/st/f1/stm32f1.dtsi:394 */
			reg = < 0x40012400 0x400 >;                                /* in zephyr/dts/arm/st/f1/stm32f1.dtsi:395 */
			clocks = < &rcc 0x18 0x200 >;                              /* in zephyr/dts/arm/st/f1/stm32f1.dtsi:396 */
			clock-names = "adcx";                                      /* in zephyr/dts/arm/st/f1/stm32f1.dtsi:397 */
			interrupts = < 0x12 0x0 >;                                 /* in zephyr/dts/arm/st/f1/stm32f1.dtsi:398 */
			#io-channel-cells = < 0x1 >;                               /* in zephyr/dts/arm/st/f1/stm32f1.dtsi:399 */
			resolutions = < 0x6000ff >;                                /* in zephyr/dts/arm/st/f1/stm32f1.dtsi:400 */
			sampling-times = < 0x2 0x8 0xe 0x1d 0x2a 0x38 0x48 0xf0 >; /* in zephyr/dts/arm/st/f1/stm32f1.dtsi:401 */
			st,adc-sequencer = "programmable";                         /* in zephyr/dts/arm/st/f1/stm32f1.dtsi:402 */
			st,adc-oversampler = "none";                               /* in zephyr/dts/arm/st/f1/stm32f1.dtsi:403 */
			st,adc-internal-regulator = "none";                        /* in zephyr/dts/arm/st/f1/stm32f1.dtsi:404 */
			status = "disabled";                                       /* in zephyr/dts/arm/st/f1/stm32f1.dtsi:405 */
			phandle = < 0x1c >;                                        /* in zephyr/dts/arm/st/f1/stm32f1.dtsi:436 */
		};

		/* node '/soc/dma@40020000' defined in zephyr/dts/arm/st/f1/stm32f1.dtsi:408 */
		dma1: dma@40020000 {
			compatible = "st,stm32-dma-v2bis";                                          /* in zephyr/dts/arm/st/f1/stm32f1.dtsi:409 */
			#dma-cells = < 0x2 >;                                                       /* in zephyr/dts/arm/st/f1/stm32f1.dtsi:410 */
			reg = < 0x40020000 0x400 >;                                                 /* in zephyr/dts/arm/st/f1/stm32f1.dtsi:411 */
			clocks = < &rcc 0x14 0x1 >;                                                 /* in zephyr/dts/arm/st/f1/stm32f1.dtsi:412 */
			interrupts = < 0xb 0x0 0xc 0x0 0xd 0x0 0xe 0x0 0xf 0x0 0x10 0x0 0x11 0x0 >; /* in zephyr/dts/arm/st/f1/stm32f1.dtsi:413 */
			status = "disabled";                                                        /* in zephyr/dts/arm/st/f1/stm32f1.dtsi:414 */
		};

		/* node '/soc/spi@40003800' defined in zephyr/dts/arm/st/f1/stm32f100Xb.dtsi:36 */
		spi2: spi@40003800 {
			compatible = "st,stm32-spi";                                                                               /* in zephyr/dts/arm/st/f1/stm32f100Xb.dtsi:37 */
			#address-cells = < 0x1 >;                                                                                  /* in zephyr/dts/arm/st/f1/stm32f100Xb.dtsi:38 */
			#size-cells = < 0x0 >;                                                                                     /* in zephyr/dts/arm/st/f1/stm32f100Xb.dtsi:39 */
			reg = < 0x40003800 0x400 >;                                                                                /* in zephyr/dts/arm/st/f1/stm32f100Xb.dtsi:40 */
			clocks = < &rcc 0x1c 0x4000 >;                                                                             /* in zephyr/dts/arm/st/f1/stm32f100Xb.dtsi:41 */
			interrupts = < 0x24 0x5 >;                                                                                 /* in zephyr/dts/arm/st/f1/stm32f100Xb.dtsi:42 */
			pinctrl-0 = < &spi2_nss_master_pb12 &spi2_sck_master_pb13 &spi2_miso_master_pb14 &spi2_mosi_master_pb15 >; /* in zephyr/boards/st/stm32vl_disco/stm32vl_disco.dts:116 */
			pinctrl-names = "default";                                                                                 /* in zephyr/boards/st/stm32vl_disco/stm32vl_disco.dts:118 */
			status = "okay";                                                                                           /* in zephyr/boards/st/stm32vl_disco/stm32vl_disco.dts:119 */
		};

		/* node '/soc/dac@40007400' defined in zephyr/dts/arm/st/f1/stm32f100Xb.dtsi:46 */
		dac1: dac@40007400 {
			compatible = "st,stm32-dac";       /* in zephyr/dts/arm/st/f1/stm32f100Xb.dtsi:47 */
			reg = < 0x40007400 0x400 >;        /* in zephyr/dts/arm/st/f1/stm32f100Xb.dtsi:48 */
			clocks = < &rcc 0x1c 0x20000000 >; /* in zephyr/dts/arm/st/f1/stm32f100Xb.dtsi:49 */
			status = "disabled";               /* in zephyr/dts/arm/st/f1/stm32f100Xb.dtsi:50 */
			#io-channel-cells = < 0x1 >;       /* in zephyr/dts/arm/st/f1/stm32f100Xb.dtsi:51 */
		};
	};

	/* node '/cpus' defined in zephyr/dts/arm/st/f1/stm32f1.dtsi:29 */
	cpus {
		#address-cells = < 0x1 >; /* in zephyr/dts/arm/st/f1/stm32f1.dtsi:30 */
		#size-cells = < 0x0 >;    /* in zephyr/dts/arm/st/f1/stm32f1.dtsi:31 */

		/* node '/cpus/cpu@0' defined in zephyr/dts/arm/st/f1/stm32f1.dtsi:33 */
		cpu0: cpu@0 {
			device_type = "cpu";                  /* in zephyr/dts/arm/st/f1/stm32f1.dtsi:34 */
			compatible = "arm,cortex-m3";         /* in zephyr/dts/arm/st/f1/stm32f1.dtsi:35 */
			cpu-power-states = < &stop0 &stop1 >; /* in zephyr/dts/arm/st/f1/stm32f1.dtsi:36 */
			reg = < 0x0 >;                        /* in zephyr/dts/arm/st/f1/stm32f1.dtsi:37 */
		};

		/* node '/cpus/power-states' defined in zephyr/dts/arm/st/f1/stm32f1.dtsi:40 */
		power-states {

			/* node '/cpus/power-states/stop0' defined in zephyr/dts/arm/st/f1/stm32f1.dtsi:41 */
			stop0: stop0 {
				compatible = "zephyr,power-state";    /* in zephyr/dts/arm/st/f1/stm32f1.dtsi:42 */
				power-state-name = "suspend-to-idle"; /* in zephyr/dts/arm/st/f1/stm32f1.dtsi:43 */
				substate-id = < 0x0 >;                /* in zephyr/dts/arm/st/f1/stm32f1.dtsi:44 */
				min-residency-us = < 0xf4240 >;       /* in zephyr/dts/arm/st/f1/stm32f1.dtsi:45 */
				exit-latency-us = < 0x190 >;          /* in zephyr/dts/arm/st/f1/stm32f1.dtsi:46 */
				phandle = < 0x18 >;                   /* in zephyr/dts/arm/st/f1/stm32f1.dtsi:36 */
			};

			/* node '/cpus/power-states/stop1' defined in zephyr/dts/arm/st/f1/stm32f1.dtsi:49 */
			stop1: stop1 {
				compatible = "zephyr,power-state";    /* in zephyr/dts/arm/st/f1/stm32f1.dtsi:50 */
				power-state-name = "suspend-to-idle"; /* in zephyr/dts/arm/st/f1/stm32f1.dtsi:51 */
				substate-id = < 0x1 >;                /* in zephyr/dts/arm/st/f1/stm32f1.dtsi:52 */
				min-residency-us = < 0xf4240 >;       /* in zephyr/dts/arm/st/f1/stm32f1.dtsi:53 */
				exit-latency-us = < 0x258 >;          /* in zephyr/dts/arm/st/f1/stm32f1.dtsi:54 */
				phandle = < 0x19 >;                   /* in zephyr/dts/arm/st/f1/stm32f1.dtsi:36 */
			};
		};
	};

	/* node '/memory@20000000' defined in zephyr/dts/arm/st/f1/stm32f1.dtsi:59 */
	sram0: memory@20000000 {
		compatible = "zephyr,memory-region",
		             "mmio-sram";            /* in zephyr/dts/arm/st/f1/stm32f1.dtsi:60 */
		zephyr,memory-region = "SRAM0";      /* in zephyr/dts/arm/st/f1/stm32f1.dtsi:61 */
		reg = < 0x20000000 0x2000 >;         /* in zephyr/dts/arm/st/f1/stm32f100Xb.dtsi:13 */
	};

	/* node '/clocks' defined in zephyr/dts/arm/st/f1/stm32f1.dtsi:64 */
	clocks {

		/* node '/clocks/clk-hse' defined in zephyr/dts/arm/st/f1/stm32f1.dtsi:65 */
		clk_hse: clk-hse {
			#clock-cells = < 0x0 >;            /* in zephyr/dts/arm/st/f1/stm32f1.dtsi:66 */
			compatible = "st,stm32-hse-clock"; /* in zephyr/dts/arm/st/f1/stm32f1.dtsi:67 */
			status = "disabled";               /* in zephyr/dts/arm/st/f1/stm32f1.dtsi:68 */
		};

		/* node '/clocks/clk-hsi' defined in zephyr/dts/arm/st/f1/stm32f1.dtsi:71 */
		clk_hsi: clk-hsi {
			#clock-cells = < 0x0 >;         /* in zephyr/dts/arm/st/f1/stm32f1.dtsi:72 */
			compatible = "fixed-clock";     /* in zephyr/dts/arm/st/f1/stm32f1.dtsi:73 */
			clock-frequency = < 0x7a1200 >; /* in zephyr/dts/arm/st/f1/stm32f1.dtsi:74 */
			status = "okay";                /* in zephyr/boards/st/stm32vl_disco/stm32vl_disco.dts:55 */
			phandle = < 0x1a >;             /* in zephyr/boards/st/stm32vl_disco/stm32vl_disco.dts:61 */
		};

		/* node '/clocks/clk-lse' defined in zephyr/dts/arm/st/f1/stm32f1.dtsi:78 */
		clk_lse: clk-lse {
			#clock-cells = < 0x0 >;       /* in zephyr/dts/arm/st/f1/stm32f1.dtsi:79 */
			compatible = "fixed-clock";   /* in zephyr/dts/arm/st/f1/stm32f1.dtsi:80 */
			clock-frequency = < 0x8000 >; /* in zephyr/dts/arm/st/f1/stm32f1.dtsi:81 */
			status = "disabled";          /* in zephyr/dts/arm/st/f1/stm32f1.dtsi:82 */
		};

		/* node '/clocks/clk-lsi' defined in zephyr/dts/arm/st/f1/stm32f1.dtsi:85 */
		clk_lsi: clk-lsi {
			#clock-cells = < 0x0 >;       /* in zephyr/dts/arm/st/f1/stm32f1.dtsi:86 */
			compatible = "fixed-clock";   /* in zephyr/dts/arm/st/f1/stm32f1.dtsi:87 */
			clock-frequency = < 0x9c40 >; /* in zephyr/dts/arm/st/f1/stm32f1.dtsi:88 */
			status = "disabled";          /* in zephyr/dts/arm/st/f1/stm32f1.dtsi:89 */
		};

		/* node '/clocks/pll' defined in zephyr/dts/arm/st/f1/stm32f100Xb.dtsi:19 */
		pll: pll {
			#clock-cells = < 0x0 >;                /* in zephyr/dts/arm/st/f1/stm32f100Xb.dtsi:20 */
			compatible = "st,stm32f100-pll-clock"; /* in zephyr/dts/arm/st/f1/stm32f100Xb.dtsi:21 */
			mul = < 0x6 >;                         /* in zephyr/boards/st/stm32vl_disco/stm32vl_disco.dts:59 */
			prediv = < 0x1 >;                      /* in zephyr/boards/st/stm32vl_disco/stm32vl_disco.dts:60 */
			clocks = < &clk_hsi >;                 /* in zephyr/boards/st/stm32vl_disco/stm32vl_disco.dts:61 */
			status = "okay";                       /* in zephyr/boards/st/stm32vl_disco/stm32vl_disco.dts:62 */
			phandle = < 0x3 >;                     /* in zephyr/boards/st/stm32vl_disco/stm32vl_disco.dts:66 */
		};
	};

	/* node '/mcos' defined in zephyr/dts/arm/st/f1/stm32f1.dtsi:99 */
	mcos {

		/* node '/mcos/mco1' defined in zephyr/dts/arm/st/f1/stm32f1.dtsi:100 */
		mco1: mco1 {
			compatible = "st,stm32f1-clock-mco"; /* in zephyr/dts/arm/st/f1/stm32f1.dtsi:101 */
			status = "disabled";                 /* in zephyr/dts/arm/st/f1/stm32f1.dtsi:102 */
		};
	};

	/* node '/power@40007000' defined in zephyr/dts/arm/st/f1/stm32f1.dtsi:418 */
	pwr: power@40007000 {
		compatible = "st,stm32-pwr"; /* in zephyr/dts/arm/st/f1/stm32f1.dtsi:419 */
		reg = < 0x40007000 0x400 >;  /* in zephyr/dts/arm/st/f1/stm32f1.dtsi:420 */
		status = "disabled";         /* in zephyr/dts/arm/st/f1/stm32f1.dtsi:421 */
		wkup-pins-nb = < 0x1 >;      /* in zephyr/dts/arm/st/f1/stm32f1.dtsi:423 */
		#address-cells = < 0x1 >;    /* in zephyr/dts/arm/st/f1/stm32f1.dtsi:425 */
		#size-cells = < 0x0 >;       /* in zephyr/dts/arm/st/f1/stm32f1.dtsi:426 */

		/* node '/power@40007000/wkup-pin@1' defined in zephyr/dts/arm/st/f1/stm32f1.dtsi:428 */
		wkup-pin@1 {
			reg = < 0x1 >;                   /* in zephyr/dts/arm/st/f1/stm32f1.dtsi:429 */
			wkup-gpios = < &gpioa 0x0 0x1 >; /* in zephyr/dts/arm/st/f1/stm32f1.dtsi:430 */
		};
	};

	/* node '/dietemp' defined in zephyr/dts/arm/st/f1/stm32f1.dtsi:434 */
	die_temp: dietemp {
		compatible = "st,stm32-temp"; /* in zephyr/dts/arm/st/f1/stm32f1.dtsi:435 */
		io-channels = < &adc1 0x10 >; /* in zephyr/dts/arm/st/f1/stm32f1.dtsi:436 */
		status = "disabled";          /* in zephyr/dts/arm/st/f1/stm32f1.dtsi:437 */
		avgslope = "4.3";             /* in zephyr/dts/arm/st/f1/stm32f1.dtsi:438 */
		ntc;                          /* in zephyr/dts/arm/st/f1/stm32f1.dtsi:440 */
		v25 = < 0x582 >;              /* in zephyr/dts/arm/st/f1/stm32f100Xb.dtsi:56 */
	};

	/* node '/smbus1' defined in zephyr/dts/arm/st/f1/stm32f1.dtsi:443 */
	smbus1: smbus1 {
		compatible = "st,stm32-smbus"; /* in zephyr/dts/arm/st/f1/stm32f1.dtsi:444 */
		#address-cells = < 0x1 >;      /* in zephyr/dts/arm/st/f1/stm32f1.dtsi:445 */
		#size-cells = < 0x0 >;         /* in zephyr/dts/arm/st/f1/stm32f1.dtsi:446 */
		i2c = < &i2c1 >;               /* in zephyr/dts/arm/st/f1/stm32f1.dtsi:447 */
		status = "disabled";           /* in zephyr/dts/arm/st/f1/stm32f1.dtsi:448 */
	};

	/* node '/smbus2' defined in zephyr/dts/arm/st/f1/stm32f1.dtsi:451 */
	smbus2: smbus2 {
		compatible = "st,stm32-smbus"; /* in zephyr/dts/arm/st/f1/stm32f1.dtsi:452 */
		#address-cells = < 0x1 >;      /* in zephyr/dts/arm/st/f1/stm32f1.dtsi:453 */
		#size-cells = < 0x0 >;         /* in zephyr/dts/arm/st/f1/stm32f1.dtsi:454 */
		i2c = < &i2c2 >;               /* in zephyr/dts/arm/st/f1/stm32f1.dtsi:455 */
		status = "disabled";           /* in zephyr/dts/arm/st/f1/stm32f1.dtsi:456 */
	};

	/* node '/leds' defined in zephyr/boards/st/stm32vl_disco/stm32vl_disco.dts:23 */
	leds {
		compatible = "gpio-leds"; /* in zephyr/boards/st/stm32vl_disco/stm32vl_disco.dts:24 */

		/* node '/leds/ld3' defined in zephyr/boards/st/stm32vl_disco/stm32vl_disco.dts:26 */
		green_led: ld3 {
			gpios = < &gpioc 0x9 0x0 >; /* in zephyr/boards/st/stm32vl_disco/stm32vl_disco.dts:27 */
			label = "User LD3";         /* in zephyr/boards/st/stm32vl_disco/stm32vl_disco.dts:28 */
		};

		/* node '/leds/ld4' defined in zephyr/boards/st/stm32vl_disco/stm32vl_disco.dts:31 */
		blue_led: ld4 {
			gpios = < &gpioc 0x8 0x0 >; /* in zephyr/boards/st/stm32vl_disco/stm32vl_disco.dts:32 */
			label = "User LD4";         /* in zephyr/boards/st/stm32vl_disco/stm32vl_disco.dts:33 */
		};
	};

	/* node '/gpio_keys' defined in zephyr/boards/st/stm32vl_disco/stm32vl_disco.dts:37 */
	gpio_keys {
		compatible = "gpio-keys"; /* in zephyr/boards/st/stm32vl_disco/stm32vl_disco.dts:38 */

		/* node '/gpio_keys/button' defined in zephyr/boards/st/stm32vl_disco/stm32vl_disco.dts:40 */
		user_button: button {
			label = "User";             /* in zephyr/boards/st/stm32vl_disco/stm32vl_disco.dts:41 */
			gpios = < &gpioa 0x0 0x1 >; /* in zephyr/boards/st/stm32vl_disco/stm32vl_disco.dts:42 */
			zephyr,code = < 0xb >;      /* in zephyr/boards/st/stm32vl_disco/stm32vl_disco.dts:43 */
		};
	};
};
